# adc_reva_me14 register map
Registers are 32-bit, read-write, no defined reset value unless marked. A register's access mark holds for its fields unless they carry their own. Offsets are from the block's base; lines under a group give offsets from that group; [hi:lo] are bit positions; {n}, {i} and the like mark numbered series; 'fields as' and 'values as' point back to an identical list; <NAME> marks a mode.

## Memory map
0x40034000 ADC size 0x1000 — 10-bit Analog to Digital Converter

## Interrupts
20 ADC — ADC IRQ

## ADC — 10-bit Analog to Digital Converter
Base 0x40034000
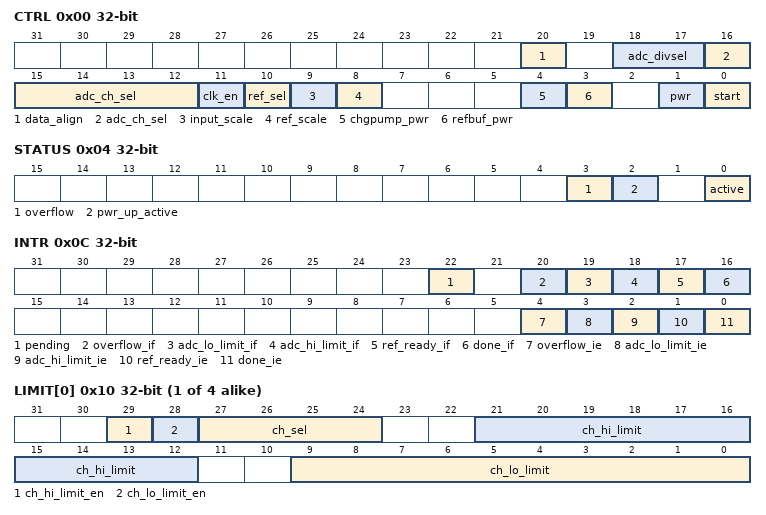
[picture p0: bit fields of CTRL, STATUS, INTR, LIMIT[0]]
0x00 CTRL — ADC Control
  [20] data_align — ADC Data Alignment Select
  [18:17] adc_divsel — Scales the external inputs, all inputs are scaled the same
    {v}=DIV{v+1} (v=0..3)
  [16:12] adc_ch_sel — ADC Channel Select
    {v}=AIN{v} (v=0..7); 8=VcoreA; 9=VcoreB; 10=Vrxout; 11=Vtxout; 12=VddA; 13=VddB/4; 14=Vddio/4; 15=Vddioh/4; 16=VregI/4
  [11] clk_en — ADC Clock Enable
  [10] ref_sel — ADC Reference Select
  [9] input_scale — ADC Input Scale
  [8] ref_scale — ADC Reference Scale
  [4] chgpump_pwr — ADC Charge Pump Enable
  [3] refbuf_pwr — ADC Reference Buffer Power Up
  [1] pwr — ADC Power Up
  [0] start — Start ADC Conversion
0x04 STATUS — ADC Status
  [3] overflow ro — ADC Overflow
  [2] pwr_up_active ro — AFE Power Up Delay Active
  [0] active ro — ADC Conversion In Progress
0x08 DATA — ADC Output Data
  [15:0] data ro — ADC Converted Sample Data Output
0x0C INTR — ADC Interrupt Control Register
  [22] pending ro — ADC Interrupt Pending Status
  [20] overflow_if write-1-clears — ADC Overflow Interrupt Flag
  [19] adc_lo_limit_if write-1-clears — ADC Lo Limit Monitor Interrupt Flag
  [18] adc_hi_limit_if write-1-clears — ADC Hi Limit Monitor Interrupt Flag
  [17] ref_ready_if write-1-clears — ADC Reference Ready Interrupt Flag
  [16] done_if write-1-clears — ADC Done Interrupt Flag
  [4] overflow_ie — ADC Overflow Interrupt Enable
  [3] adc_lo_limit_ie — ADC Lo Limit Monitor Interrupt Enable
  [2] adc_hi_limit_ie — ADC Hi Limit Monitor Interrupt Enable
  [1] ref_ready_ie — ADC Reference Ready Interrupt Enable
  [0] done_ie — ADC Done Interrupt Enable
{0x10+4i} LIMIT[{i}] (i=0..3) — ADC Limit
  [29] ch_hi_limit_en — High Limit Monitoring Enable
  [28] ch_lo_limit_en — Low Limit Monitoring Enable
  [27:24] ch_sel — ADC Channel Select
  [21:12] ch_hi_limit — High Limit Threshold
  [9:0] ch_lo_limit — Low Limit Threshold
